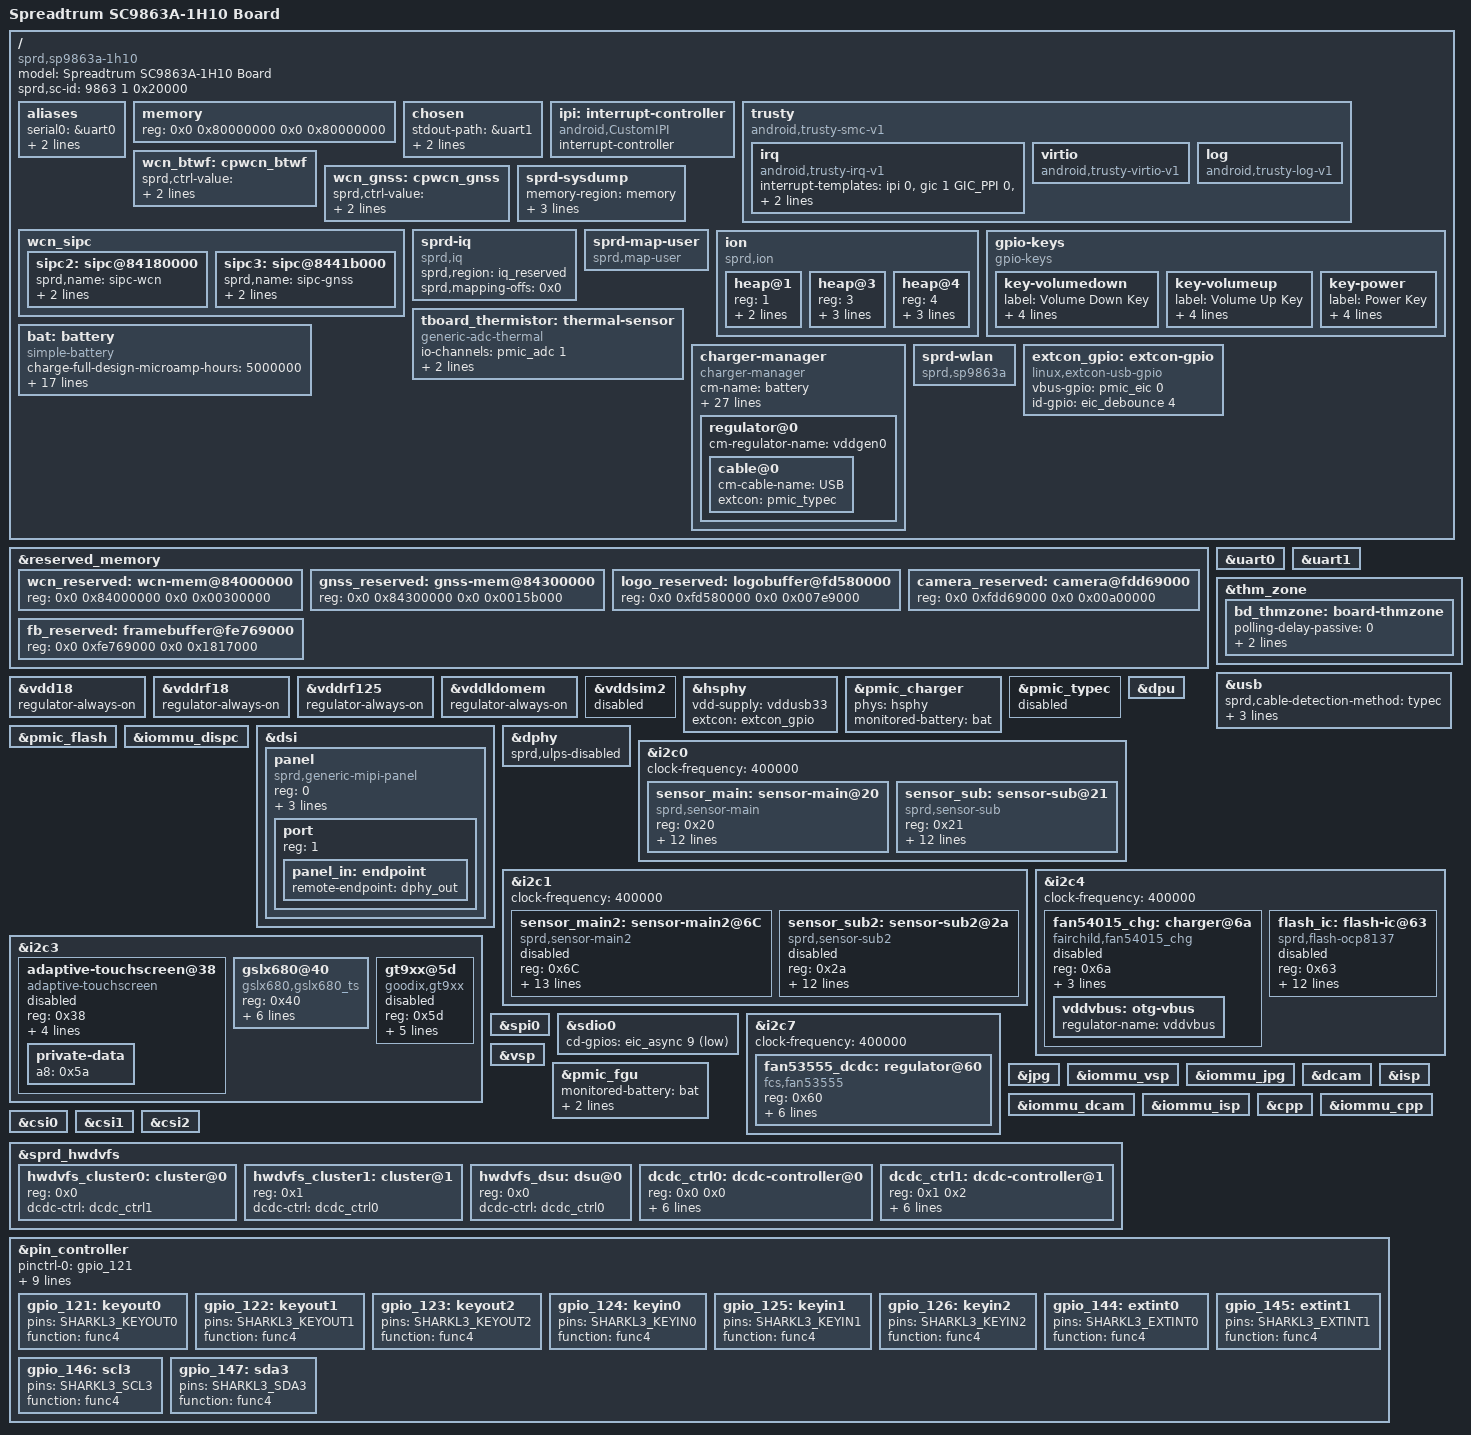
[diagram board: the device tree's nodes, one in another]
// SPDX-License-Identifier: (GPL-2.0+ OR MIT)
/*
 * Spreadtrum Sharkl3 platform DTS file
 *
 * Copyright (C) 2018, Spreadtrum Communications Inc.
 */

/dts-v1/;

#include "sc9863a.dtsi"
#include "sc9863a-wcn.dtsi"
#include "sp9863a-mach.dtsi"
#include "lcd/lcd_nt35695_truly_mipi_fhd.dtsi"
#include "lcd/lcd_nt35532_truly_mipi_fhd.dtsi"
#include "lcd/lcd_nt35596_boe_mipi_fhd.dtsi"
#include "lcd/lcd_sc9863a_ek79007_boe_4lane_mipi_wvga.dtsi"
#include "lcd/lcd_sc9863a_jd9365_boe_sq_mipi_hd.dtsi"
#include "lcd/lcd_s9863a_fx_boe_9881c_mipi.dtsi"
#include "lcd/lcd_sc9863a_jd9366_boe_jlt_mipi_hd.dtsi"
#include "lcd/lcd_sc9863_hjc_hx8279_mipi_fhd.dtsi"
#include "lcd/lcd_sc9863_qc_hx8279_mipi_fhd.dtsi"
#include "lcd/lcd_sc9863_ota7290b_boe_fx_mipi_fhd.dtsi"
#include "lcd/lcd_sc9863a_9367_boe_qc_mipi_hd.dtsi"
#include "lcd/lcd_sc9863a_9365da_qc_jlt_mipi_hd.dtsi"
#include "lcd/lcd_s9863a_fx_boe_jd9365_mipi_hd.dtsi"
#include "lcd/lcd_sc9863a_sl_fhd_ek79208_mipi.dtsi"
#include "lcd/lcd_9863a_sat_boe_9365da_mipi.dtsi"
#include <dt-bindings/gpio/gpio.h>
#include <dt-bindings/input/input.h>

/ {
	model = "Spreadtrum SC9863A-1H10 Board";

	compatible = "sprd,sp9863a-1h10", "sprd,sc9863a";

	sprd,sc-id = <9863 1 0x20000>;

	aliases {
		serial0 = &uart0;
		serial1 = &uart1;
		i2c3 = &i2c3;
	};

	memory: memory {
		device_type = "memory";
		reg = <0x0 0x80000000 0x0 0x80000000>;
	};

	chosen {
		stdout-path = &uart1;
		bootargs = "earlycon=sprd_serial,0x70100000,115200n8 console=ttyS1,115200n8 loglevel=1 init=/init root=/dev/ram0 rw androidboot.hardware=s9863a1h10 androidboot.dtbo_idx=0 printk.devkmsg=on androidboot.boot_devices=soc/soc:ap-ahb/20600000.sdio";
	};

	ipi: interrupt-controller {
		compatible = "android,CustomIPI";
		#interrupt-cells = <1>;
		interrupt-controller;
	};

	trusty {
		compatible = "android,trusty-smc-v1";

		irq {
			compatible = "android,trusty-irq-v1";
			interrupt-templates = <&ipi 0>,
						<&gic 1 GIC_PPI 0>,
						<&gic 1 GIC_SPI 0>;
			interrupt-ranges = < 0  15 0>,
						<16  31 1>,
						<32 223 2>;
		};

		virtio {
			compatible = "android,trusty-virtio-v1";
		};

		log {
			compatible = "android,trusty-log-v1";
		};
	};

	/* WCN BASE mem adjust */
	wcn_btwf: cpwcn_btwf {
		sprd,ctrl-value = <0x03000000 0x0102 0x03000000
				  0x00080000 0x00010400 0x80>;
		reg = <0x0 0x84000000 0x0 0x180000>;
	};

	wcn_gnss: cpwcn_gnss {
		sprd,ctrl-value = <0x00300000 0x0102 0x03000000
				  0x00080000 0x00010800 0x40>;
		reg = <0x0 0x84300000 0x0 0x100000>;
	};

	wcn_sipc {
		/delete-node/ sipc@88180000;
		/delete-node/ sipc@8841b000;
		sipc2: sipc@84180000 {
			sprd,name = "sipc-wcn";
			sprd,dst = <3 5>; /* <dst core-id> */
			/* <ap-addr dst-maped-addr size> */
			sprd,smem-info = <0x84180000 0x00180000 0x180000>;
		};
		sipc3: sipc@8441b000 {
			sprd,name = "sipc-gnss";
			sprd,dst = <4 6>; /* <dst core-id> */
			/* <ap-addr dst-maped-addr size> */
			sprd,smem-info = <0x8441b000 0x11b000 0x32000>;
		};
	};

	sprd-sysdump {
		memory-region = <&memory>;
		memory-region-re = <&cp_reserved>, <&scproc_pubpm>, <&smem_reserved>,
				<&gnss_reserved>, <&wcn_reserved>;
		memory-region-se = <&tos_reserved>, <&sml_reserved>;
	};

	sprd-iq {
		compatible = "sprd,iq";
		sprd,region = <&iq_reserved>;
		sprd,mapping-offs = <0x0>;
	};

	sprd-map-user {
		compatible = "sprd,map-user";
	};

	ion {
		compatible = "sprd,ion";
		#address-cells = <1>;
		#size-cells = <0>;

		heap@1 {
			reg = <1>;
			label = "carveout_mm";
			type = <2>;
		};

		heap@3 {
			reg = <3>;
			label = "carveout_fb";
			type = <2>;
			memory-region = <&fb_reserved>;
		};

		heap@4 {
			reg = <4>;
			label = "carveout_camera";
			type = <2>;
			memory-region = <&camera_reserved>;
		};
	};

	gpio-keys {
		compatible = "gpio-keys";

		key-volumedown {
			label = "Volume Down Key";
			linux,code = <KEY_VOLUMEDOWN>;
			gpios = <&ap_gpio 124 GPIO_ACTIVE_LOW>;
			debounce-interval = <2>;
			wakeup-source;
		};

		key-volumeup {
			label = "Volume Up Key";
			linux,code = <KEY_VOLUMEUP>;
			gpios = <&ap_gpio 125 GPIO_ACTIVE_LOW>;
			debounce-interval = <2>;
			wakeup-source;
		};

		key-power {
			label = "Power Key";
			linux,code = <KEY_POWER>;
			gpios = <&pmic_eic 1 GPIO_ACTIVE_LOW>;
			debounce-interval = <2>;
			wakeup-source;
		};
	};

	tboard_thermistor:thermal-sensor {
		compatible = "generic-adc-thermal";
		#thermal-sensor-cells = <0>;
		io-channels = <&pmic_adc 1>;
		io-channel-names = "sensor-channel";
		temperature-lookup-table = <	(-39742) 1131
						(-29777) 1110
						(-19480) 1074
						(-4679) 983
						10110 838
						24805 654
						44922 413
						54903 316
						64895 238
						74884 178
						84883 133
						94883 100
						104880 75
						114889 57
						124872 43 >;
	};

	bat: battery {
		compatible = "simple-battery";
		charge-full-design-microamp-hours = <5000000>;
		charge-term-current-microamp = <120000>;
		constant_charge_voltage_max_microvolt = <4350000>;
		factory-internal-resistance-micro-ohms = <100000>;
		voltage-min-design-microvolt = <3450000>;
		ocv-capacity-celsius = <20>;
		ocv-capacity-table-0 = <4316000 100>, <4240000 95>, <4179000 90>,
					<4123000 85>, <4081000 80>, <4034000 75>,
					<3991000 70>, <3953000 65>, <3910000 60>,
					<3876000 55>, <3838000 50>, <3814000 45>,
					<3795000 40>, <3785000 35>, <3774000 30>,
					<3761000 25>, <3743000 20>, <3716000 15>,
					<3680000 10>, <3628000 5>, <3500000 0>;
	/*	voltage-temp-table = <1242000 750>, <1132000 800>, <1022000 850>, 
				      <886000 900>,  <803000 950>, <691000 1000>, 
				      <608000 1050>, <512000 1100>, <448000 1150>, 
				      <376000 1200>, <325000 1250>, <278000 1300>, 
				      <237000 1350>, <203000 1400>, <175000 1450>,
				      <148000 1500>, <128000 1550>, <118000 1600>; */
		charge-sdp-current-microamp = <1650000 1850000>;
		charge-dcp-current-microamp = <1650000 1850000>;
		charge-cdp-current-microamp = <1650000 1850000>;
		charge-unknown-current-microamp = <1650000 1850000>;
	};

	charger-manager {
		compatible = "charger-manager";
		cm-name = "battery";
		cm-poll-mode = <2>;
		cm-poll-interval = <15000>;
		cm-battery-stat = <2>;

		cm-fullbatt-vchkdrop-ms = <30000>;
		cm-fullbatt-vchkdrop-volt = <60000>;
		cm-fullbatt-voltage = <4330000>;
		cm-fullbatt-current = <150000>;
		cm-fullbatt-capacity = <100>;

		cm-num-chargers = <1>;
		cm-chargers = "sc2721_charger";
		cm-fuel-gauge = "sc27xx-fgu";

		/* in deci centigrade */
		cm-battery-cold = <200>;
		cm-battery-cold-in-minus;
		cm-battery-hot = <800>;
		cm-battery-temp-diff = <100>;

		/* Allow charging for 6hr */
		cm-charging-max = <21600000>;
		/* recovery charging after stop charging 45min */
		cm-discharging-max = <2700000>;

		/* the interval to feed charger watchdog */
		cm-wdt-interval = <60>;

		/* drop voltage in microVolts to allow shutdown */
		cm-shutdown-voltage = <3100000>;

		/* when 99% of the time is exceeded, it will be forced to 100% */
		cm-tickle-time-out = <500>;

		/* how much time to allow capacity change */
		cm-one-cap-time = <30>;

		/* when the safe charging voltage is exceeded, stop charging */
		cm-charge-voltage-max = <6500000>;
		/* drop voltage in microVolts to restart charging */
		cm-charge-voltage-drop = <700000>;
		cm-jeita-temp-table = <1000 1050 0 4360000>, <1150 1180 1800000 4360000>,
				<1410 1350 1800000 4360000>, <1480 1450 0 4360000>;
		regulator@0 {
			cm-regulator-name = "vddgen0";
			cable@0 {
				cm-cable-name = "USB";
				extcon = <&pmic_typec>;
			};
		};
	};

	sprd-wlan {
		compatible = "sprd,sp9863a";
	};

	extcon_gpio: extcon-gpio {
		compatible = "linux,extcon-usb-gpio";
		vbus-gpio = <&pmic_eic 0 GPIO_ACTIVE_HIGH>;
		id-gpio = <&eic_debounce 4 GPIO_ACTIVE_HIGH>;
	};
};

&reserved_memory {

	wcn_reserved: wcn-mem@84000000 {
		reg = <0x0 0x84000000 0x0 0x00300000>;
	};

	gnss_reserved: gnss-mem@84300000 {
		reg = <0x0 0x84300000 0x0 0x0015b000>;
	};

	logo_reserved: logobuffer@fd580000{
		reg = <0x0 0xfd580000 0x0 0x007e9000>;
	};

	camera_reserved: camera@fdd69000{
		reg = <0x0 0xfdd69000 0x0 0x00a00000>;
	};

	fb_reserved: framebuffer@fe769000 {
		reg = <0x0 0xfe769000 0x0 0x1817000>;
	};
};

&uart0 {
	status = "okay";
};

&uart1 {
	status = "okay";
};

&thm_zone {
	bd_thmzone: board-thmzone {
		polling-delay-passive = <0>;
		polling-delay = <0>;
		thermal-sensors = <&tboard_thermistor>;
	};
};

&usb {
	sprd,cable-detection-method = "typec";
};

&vdd18 {
	regulator-always-on;
};

&vddrf18 {
	regulator-always-on;
};

&vddrf125 {
	regulator-always-on;
};

&vddldomem {
	regulator-always-on;
};

&vddsim2 {
	status = "disabled";
};

&hsphy {
	vdd-supply = <&vddusb33>;
	extcon = <&extcon_gpio>;
};

&usb {
	extcon = <&extcon_gpio>;
	vbus-supply = <&vddvbus>;
	sprd,otg-gpios = <&ap_gpio 8 GPIO_ACTIVE_LOW>;
};

&pmic_charger {
	status = "okay";
	phys = <&hsphy>;
	monitored-battery = <&bat>;
};

&pmic_typec {
	status = "disabled";
};

&dpu {
	status = "okay";
};

&pmic_flash {
	status = "okay";
};
	
&iommu_dispc {
	status = "okay";
};

&dsi {
	status = "okay";
	#address-cells = <1>;
	#size-cells = <0>;

	panel: panel {
		compatible = "sprd,generic-mipi-panel";
		#address-cells = <1>;
		#size-cells = <0>;
		reg = <0>;

		avdd-gpio = <&ap_gpio 89 GPIO_ACTIVE_HIGH>;
		avee-gpio = <&ap_gpio 9 GPIO_ACTIVE_HIGH>;
/*		avee-gpio = <&ap_gpio 32 GPIO_ACTIVE_HIGH>;    for P30   */
		reset-gpio = <&ap_gpio 50 GPIO_ACTIVE_HIGH>;
		port {
			reg = <1>;
			panel_in: endpoint {
				remote-endpoint = <&dphy_out>;
			};
		};
	};
};

&dphy {
	status = "okay";
	sprd,ulps-disabled;
};

&i2c0 {
	status = "okay";
	clock-frequency = <400000>;

	sensor_main: sensor-main@20 {
		compatible = "sprd,sensor-main";
		reg = <0x20>;
		clock-names = "clk_src","sensor_eb",
			"clk_96m","clk_76m8",
			"clk_48m","clk_26m";
		clocks = <&aon_clk CLK_SENSOR0>, <&mm_gate CLK_SENSOR0_EB>,
			<&pll CLK_TWPLL_96M>,<&pll CLK_TWPLL_76M8>,
			<&pll CLK_TWPLL_48M>,<&ext_26m>;
		vddio-supply = <&vddcamio>;
		vddcama-supply = <&vddcama>;
		vddcamd-supply = <&vddcamd>;
		vddcammot-supply = <&vddcammot>;
		sprd,phyid = <1>;
		csi = <&csi0>;
		reset-gpios = <&ap_gpio 44 0>;
		power-down-gpios = <&ap_gpio 46 0>;
	};

	sensor_sub: sensor-sub@21 {
		compatible = "sprd,sensor-sub";
		reg = <0x21>;
		clock-names = "clk_src","sensor_eb",
			"clk_96m","clk_76m8",
			"clk_48m","clk_26m";
		clocks = <&aon_clk CLK_SENSOR0>, <&mm_gate CLK_SENSOR0_EB>,
			<&pll CLK_TWPLL_96M>,<&pll CLK_TWPLL_76M8>,
			<&pll CLK_TWPLL_48M>,<&ext_26m>;
		vddio-supply = <&vddcamio>;
		vddcama-supply = <&vddcama>;
		vddcamd-supply = <&vddcamd>;
		vddcammot-supply = <&vddcammot>;
		sprd,phyid = <3>;
		csi = <&csi1>;
		reset-gpios = <&ap_gpio 44 0>;
		power-down-gpios = <&ap_gpio 40 0>;
	};
};

&i2c1 {
	status = "okay";
	clock-frequency = <400000>;
	
	sensor_main2: sensor-main2@6C {
		status = "disabled";
		compatible = "sprd,sensor-main2";
		reg = <0x6C>;
		clock-names = "clk_src","sensor_eb",
			"clk_96m","clk_76m8",
			"clk_48m","clk_26m";
		clocks = <&aon_clk CLK_SENSOR1>, <&mm_gate CLK_SENSOR1_EB>,
			<&pll CLK_TWPLL_96M>,<&pll CLK_TWPLL_76M8>,
			<&pll CLK_TWPLL_48M>,<&ext_26m>;
		vddio-supply = <&vddcamio>;
		vddcama-supply = <&vddcama>;
		vddcamd-supply = <&vddcamd>;
		vddcammot-supply = <&vddcammot>;
		sprd,phyid = <3>;
		csi = <&csi1>;
		/*avdd-gpios=<&ap_gpio 140 0>;*/
		dvdd-gpios=<&ap_gpio 62 0>;
		reset-gpios = <&ap_gpio 45 0>;
		power-down-gpios = <&ap_gpio 47 0>;
	};

	sensor_sub2: sensor-sub2@2a {
		status = "disabled";
		compatible = "sprd,sensor-sub2";
		reg = <0x2a>;
		clock-names = "clk_src","sensor_eb",
			"clk_96m","clk_76m8",
			"clk_48m","clk_26m";
		clocks = <&aon_clk CLK_SENSOR1>, <&mm_gate CLK_SENSOR1_EB>,
			<&pll CLK_TWPLL_96M>,<&pll CLK_TWPLL_76M8>,
			<&pll CLK_TWPLL_48M>,<&ext_26m>;
		vddio-supply = <&vddcamio>;
		vddcama-supply = <&vddcama>;
		vddcamd-supply = <&vddcamd>;
		vddcammot-supply = <&vddcammot>;
		sprd,phyid = <4>;
		csi = <&csi2>;
		/*avdd-gpios=<&ap_gpio 140 0>;*/
		reset-gpios = <&ap_gpio 45 0>;
		power-down-gpios = <&ap_gpio 40 0>;
	};
};

&i2c3 {
	status = "okay";

	adaptive-touchscreen@38 {
		status = "disabled";
		compatible = "adaptive-touchscreen";
		reg = <0x38>;
		gpios = <&ap_gpio 145 GPIO_ACTIVE_HIGH
			&ap_gpio 144 GPIO_ACTIVE_HIGH>;
		controller = "focaltech,FT5436";
		virtualkeys = <580 60 1320 60 45
			172 360 1320 60 45
			158 600 1320 60 45>;
		private-data {
			a8 = /bits/ 8 <0x5a>;
		};
	};
	
	gslx680@40{
		compatible = "gslx680,gslx680_ts";
		reg = <0x40>;
		gpios = <&ap_gpio 145 GPIO_ACTIVE_HIGH
			&ap_gpio 144 GPIO_ACTIVE_HIGH>;
		vdd_name = "vdd28";
		virtualkeys = <100 1020 80 65
      280 1020 80 65
      470 1020 80 65>;
		TP_MAX_X = <600>;
		TP_MAX_Y = <1024>;
	};	
        gt9xx@5d{
                status = "disabled";
                compatible = "goodix,gt9xx";
                reg = <0x5d>;
                //gpios = <&ap_gpio 145 0
                 //       &ap_gpio 144 0>;
		goodix,reset-gpio = <&ap_gpio 145 GPIO_ACTIVE_HIGH>;
		goodix,irq-gpio = <&ap_gpio 144 GPIO_ACTIVE_HIGH>;
                vdd_name = "vdd28";
                virtualkeys = <80 1350 30 30
                                        240 1350 30 30
                                        400 1350 30 30>;
		};
};

&i2c4 {
	status = "okay";
	clock-frequency = <400000>;

	fan54015_chg: charger@6a {
		status = "disabled";
		compatible = "fairchild,fan54015_chg";
		reg = <0x6a>;
		phys = <&hsphy>;
		monitored-battery = <&bat>;
		extcon = <&extcon_gpio>;
		vddvbus:otg-vbus {
			regulator-name = "vddvbus";
		};
	};

	flash_ic: flash-ic@63 {
		status = "disabled";
		compatible = "sprd,flash-ocp8137";
		reg = <0x63>;
		sprd,flash-ic = <8137>;
		sprd,torch = <1>;
		sprd,preflash = <1>;
		sprd,highlight = <1>;
		sprd,torch-level = <128>;
		sprd,preflash-level = <128>;
		sprd,highlight-level = <128>;
		sprd,lvfm-enable = <1>;
		flash-torch-en-gpios = <&ap_gpio 88 0>;
		flash-chip-en-gpios = <&ap_gpio 89 0>;
		flash-en-gpios = <&ap_gpio 76 0>;
		flash-sync-gpios = <&ap_gpio 141 0>;
	};
};

&spi0 {
	/*used for fingerprint sensor*/
	status = "okay";
};

&sdio0 {
	cd-gpios = <&eic_async 9 1>;
};

&i2c7 {
	status = "okay";
	clock-frequency = <400000>;

	fan53555_dcdc: regulator@60 {
		compatible = "fcs,fan53555";
		reg = <0x60>;
		regulator-name = "fan53555";
		regulator-min-microvolt = <603000>;
		regulator-max-microvolt = <1411000>;
		regulator-ramp-delay = <64000>;
		regulator-always-on;
		fcs,suspend-voltage-selector = <1>;
	};
};

&vsp {
	status = "okay";
};

&pmic_fgu {
	monitored-battery = <&bat>;
	sprd,calib-resistance-real = <20000>;
	sprd,calib-resistance-spec = <20000>;
};

&jpg {
	status = "okay";
};

&iommu_vsp {
	status = "okay";
};

&iommu_jpg {
	status = "okay";
};

&dcam {
	status = "okay";
};

&iommu_dcam {
	status = "okay";
};

&isp {
	status = "okay";
};

&iommu_isp {
	status = "okay";
};

&cpp {
	status = "okay";
};

&iommu_cpp {
	status = "okay";
};

&csi0 {
	status = "okay";
};

&csi1 {
	status = "okay";
};

&csi2 {
	status = "okay";
};

&sprd_hwdvfs {
	hwdvfs_cluster0: cluster@0 {
		reg = <0x0>;
		dcdc-ctrl = <&dcdc_ctrl1>;
	};

	hwdvfs_cluster1: cluster@1 {
		reg = <0x1>;
		dcdc-ctrl = <&dcdc_ctrl0>;
	};

	hwdvfs_dsu: dsu@0 {
		reg = <0x0>;
		dcdc-ctrl = <&dcdc_ctrl0>;
	};

	dcdc_ctrl0: dcdc-controller@0 {
		reg = <0x0 0x0>;
		volt-via-adi;
		volt-hold-us = <50>;
		volt-pause-us = <5>;
		volt-timeout-us = <800>;
		volt-stable-us  = <5>;
		volt-max-step-microvolt = <25000>;
	};

	dcdc_ctrl1: dcdc-controller@1 {
		reg = <0x1 0x2>;
		volt-via-i2c;
		volt-hold-us = <25>;
		volt-pause-us = <20>;
		volt-timeout-us = <800>;
		volt-stable-us  = <25>;
		volt-max-step-microvolt = <1200004>;
	};
};

&pin_controller {
	pinctrl-names =
	/* keyout0 ~ keyout2 */
	"gpio_121", "gpio_122", "gpio_123",
	/* keyin0 ~ keyin2 */
	"gpio_124", "gpio_125", "gpio_126",
	/* extint0, extint1, scl3, sda3 */
	"gpio_144", "gpio_145", "gpio_146", "gpio_147";
	pinctrl-0 = <&gpio_121>;
	pinctrl-1 = <&gpio_122>;
	pinctrl-2 = <&gpio_123>;
	pinctrl-3 = <&gpio_124>;
	pinctrl-4 = <&gpio_125>;
	pinctrl-5 = <&gpio_126>;
	pinctrl-6 = <&gpio_144>;
	pinctrl-7 = <&gpio_145>;
	pinctrl-8 = <&gpio_146>;
	pinctrl-9 = <&gpio_147>;

	gpio_121: keyout0 {
		pins = "SHARKL3_KEYOUT0";
		function = "func4";
	};

	gpio_122: keyout1 {
		pins = "SHARKL3_KEYOUT1";
		function = "func4";
	};

	gpio_123: keyout2 {
		pins = "SHARKL3_KEYOUT2";
		function = "func4";
	};

	gpio_124: keyin0 {
		pins = "SHARKL3_KEYIN0";
		function = "func4";
	};

	gpio_125: keyin1 {
		pins = "SHARKL3_KEYIN1";
		function = "func4";
	};

	gpio_126: keyin2 {
		pins = "SHARKL3_KEYIN2";
		function = "func4";
	};

	gpio_144: extint0 {
		pins = "SHARKL3_EXTINT0";
		function = "func4";
	};

	gpio_145: extint1 {
		pins = "SHARKL3_EXTINT1";
		function = "func4";
	};

	gpio_146: scl3 {
		pins = "SHARKL3_SCL3";
		function = "func4";
	};

	gpio_147: sda3 {
		pins = "SHARKL3_SDA3";
		function = "func4";
	};
};
